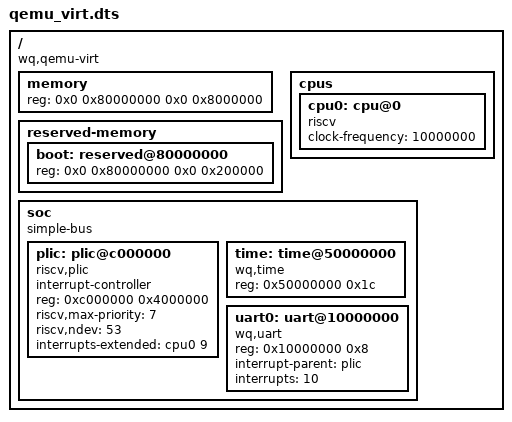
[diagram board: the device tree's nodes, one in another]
/dts-v1/;
/ {
    #address-cells = <2>;
    #size-cells = <2>;
    compatible = "wq,qemu-virt";

    memory {
        device_type = "memory";
        reg = < 0x0 0x80000000 0x0 0x8000000>; 
    };

    reserved-memory {
        #address-cells = <2>;
        #size-cells = <2>;
        ranges;
        boot: reserved@80000000 {
            reg = <0x0 0x80000000 0x0 0x200000>; // 保留内存区域
        };
    };

    cpus {
        // compatible = "riscv";
        #address-cells = <1>;
        #size-cells = <1>;
        cpu0: cpu@0 {
            compatible = "riscv";
            device_type = "cpu";
            clock-frequency = <10000000>;
        };
    };

    soc {
        #address-cells = <1>;
        #size-cells = <1>;
        compatible = "simple-bus";

        plic: plic@c000000 {
            compatible = "riscv,plic";
            interrupt-controller;
            reg = <0xc000000 0x4000000>;
            #interrupt-cells = <1>;
            riscv,max-priority = <7>;
            riscv,ndev = <53>;       // 支持的外设中断数量
            interrupts-extended = <&cpu0 9>; // 通知目标CPU
        };
       
        time: time@50000000 {
            compatible = "wq,time";
            reg = <0x50000000 0x1c>;
        };
  
        uart0: uart@10000000 {
            compatible = "wq,uart";
            reg = <0x10000000 0x8>;
            interrupt-parent = <&plic>;
            interrupts = <10>;
        };

    };
};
